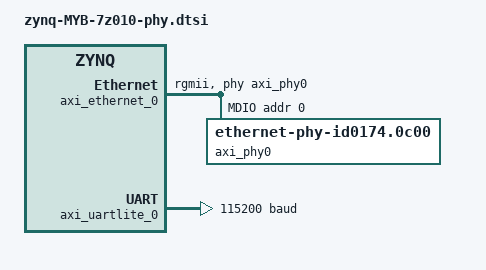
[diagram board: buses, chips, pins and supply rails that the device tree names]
/*
 * CAUTION: This file is automatically generated by Xilinx.
 * Version: XSCT 2018.3
 * Today is: Wed May 29 17:03:00 2019
 */


/ {
	amba_pl: amba_pl {
		#address-cells = <1>;
		#size-cells = <1>;
		compatible = "simple-bus";
		ranges ;
		axi_dma_0: dma@40400000 {
			#dma-cells = <1>;
			axistream-connected = <&axi_ethernet_0>;
			axistream-control-connected = <&axi_ethernet_0>;
			clock-names = "s_axi_lite_aclk", "m_axi_sg_aclk", "m_axi_mm2s_aclk", "m_axi_s2mm_aclk";
			clocks = <&clkc 17>, <&clkc 16>, <&clkc 16>, <&clkc 16>;
			compatible = "xlnx,eth-dma";
			interrupt-names = "mm2s_introut", "s2mm_introut";
			interrupt-parent = <&intc>;
			interrupts = <0 29 4 0 30 4>;
			reg = <0x40400000 0x10000>;
			xlnx,include-dre ;
		};
		axi_ethernet_0: ethernet@43c00000 {
			axistream-connected = <&axi_dma_0>;
			axistream-control-connected = <&axi_dma_0>;
			clock-frequency = <100000000>;
			clock-names = "s_axi_lite_clk", "axis_clk", "gtx_clk", "ref_clk";
			clocks = <&clkc 17>, <&clkc 16>, <&clkc 16>, <&clkc 15>;
			compatible = "xlnx,axi-ethernet-7.1", "xlnx,axi-ethernet-1.00.a";
			device_type = "network";
			interrupt-names = "interrupt";
			interrupt-parent = <&intc>;
			interrupts = <0 31 4>;
			local-mac-address = [00 0a 35 00 01 02];
			phy-handle = <&axi_phy0>;
			phy-mode = "rgmii";
			reg = <0x43c00000 0x40000>;
			xlnx = <0x0>;
			xlnx,axiliteclkrate = <0x0>;
			xlnx,axisclkrate = <0x0>;
			xlnx,clockselection = <0x0>;
			xlnx,enableasyncsgmii = <0x0>;
			xlnx,gt-type = <0x0>;
			xlnx,gtinex = <0x0>;
			xlnx,gtlocation = <0x0>;
			xlnx,gtrefclksrc = <0x0>;
			xlnx,include-dre ;
			xlnx,instantiatebitslice0 = <0x0>;
			xlnx,phy-type = <0x3>;
			xlnx,phyaddr = <0x1>;
			xlnx,rable = <0x0>;
			xlnx,rxcsum = <0x2>;
			xlnx,rxlane0-placement = <0x0>;
			xlnx,rxlane1-placement = <0x0>;
			xlnx,rxmem = <0x4000>;
			xlnx,rxnibblebitslice0used = <0x0>;
			xlnx,tx-in-upper-nibble = <0x1>;
			xlnx,txcsum = <0x2>;
			xlnx,txlane0-placement = <0x0>;
			xlnx,txlane1-placement = <0x0>;
			axi_ethernet_0_mdio: mdio {
				#address-cells = <1>;
				#size-cells = <0>;

				axi_phy0: phy@0 {
					// compatible = "ethernet-phy-id0022.1620"; //Micrel phy id
					compatible = "ethernet-phy-id0174.0c00"; //Xilinx phy id
					device_type = "ethernet-phy";
					xlnx,phy-type = <0x5>;
					reg = <0x0>;
					linux,phandle = <0x8>;
					phandle = <0x8>;
				};
			};
		};
		axi_uartlite_0: serial@42c00000 {
			clock-names = "s_axi_aclk";
			clocks = <&clkc 17>;
			compatible = "xlnx,axi-uartlite-2.0", "xlnx,xps-uartlite-1.00.a";
			current-speed = <115200>;
			device_type = "serial";
			interrupt-names = "interrupt";
			interrupt-parent = <&intc>;
			interrupts = <0 32 1>;
			port-number = <0>;
			reg = <0x42c00000 0x10000>;
			xlnx,baudrate = <0x1c200>;
			xlnx,data-bits = <0x8>;
			xlnx,odd-parity = <0x0>;
			xlnx,s-axi-aclk-freq-hz-d = "100.0";
			xlnx,use-parity = <0x0>;
		};
	};
};
